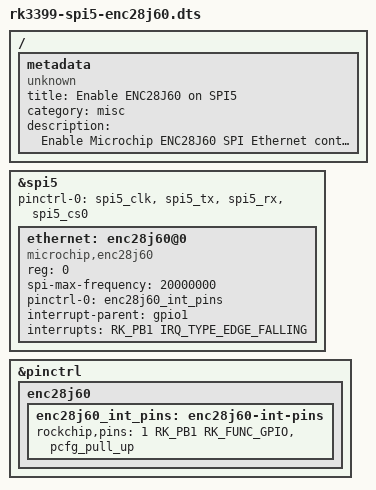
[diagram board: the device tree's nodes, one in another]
/dts-v1/;
/plugin/;

#include <dt-bindings/gpio/gpio.h>
#include <dt-bindings/pinctrl/rockchip.h>
#include <dt-bindings/interrupt-controller/irq.h>

/ {
	metadata {
		title = "Enable ENC28J60 on SPI5";
		compatible = "unknown";
		category = "misc";
		description = "Enable Microchip ENC28J60 SPI Ethernet controller on SPI5.
Warning: this overlay is only compatiable with Liwan, which is a customized version of ROCK 4C.
This overlay is NOT compatiable with regular ROCK 4C.";
	};
};

&spi5 {
	status = "okay";
	#address-cells = <1>;
	#size-cells = <0>;
	pinctrl-names = "default";
	pinctrl-0 = <&spi5_clk &spi5_tx &spi5_rx &spi5_cs0>;

	ethernet: enc28j60@0 {
		compatible = "microchip,enc28j60";
		reg = <0>;
		spi-max-frequency = <20000000>;

		pinctrl-names = "default";
		pinctrl-0 = <&enc28j60_int_pins>;

		interrupt-parent = <&gpio1>;
		interrupts = <RK_PB1 IRQ_TYPE_EDGE_FALLING>;
	};
};

&pinctrl {
	enc28j60 {
		enc28j60_int_pins: enc28j60-int-pins {
			rockchip,pins = <1 RK_PB1 RK_FUNC_GPIO &pcfg_pull_up>;
		};
	};
};
